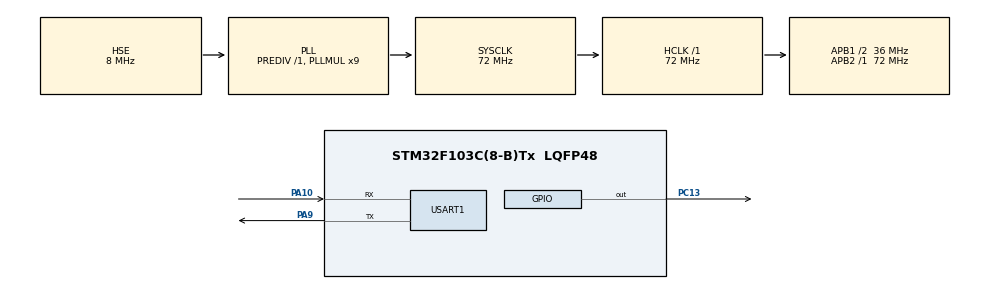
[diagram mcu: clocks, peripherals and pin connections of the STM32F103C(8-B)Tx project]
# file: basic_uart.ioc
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Dma.Request0=USART1_RX
Dma.USART1_RX.0.Direction=DMA_PERIPH_TO_MEMORY
Dma.USART1_RX.0.Instance=DMA1_Channel5
Dma.USART1_RX.0.MemDataAlignment=DMA_MDATAALIGN_BYTE
Dma.USART1_RX.0.MemInc=DMA_MINC_ENABLE
Dma.USART1_RX.0.Mode=DMA_CIRCULAR
Dma.USART1_RX.0.PeriphDataAlignment=DMA_PDATAALIGN_BYTE
Dma.USART1_RX.0.PeriphInc=DMA_PINC_DISABLE
Dma.USART1_RX.0.Priority=DMA_PRIORITY_LOW
Mcu.Family=STM32F1
Mcu.Name=STM32F103C(8-B)Tx
Mcu.Package=LQFP48
NVIC.DMA1_Channel5_IRQn=true\:0\:0\:false\:false\:true
NVIC.PriorityGroup=NVIC_PRIORITYGROUP_4
NVIC.USART1_IRQn=true\:0\:0\:false\:false\:true
PA10.Mode=Asynchronous
PA10.Signal=USART1_RX
PA13.Mode=Serial_Wire
PA13.Signal=SYS_JTMS-SWDIO
PA14.Mode=Serial_Wire
PA14.Signal=SYS_JTCK-SWCLK
PA9.Mode=Asynchronous
PA9.Signal=USART1_TX
PC13-TAMPER-RTC.Signal=GPIO_Output
PD0-OSC_IN.Mode=HSE-External-Oscillator
PD0-OSC_IN.Signal=RCC_OSC_IN
PD1-OSC_OUT.Mode=HSE-External-Oscillator
PD1-OSC_OUT.Signal=RCC_OSC_OUT
ProjectManager.HeapSize=0x200
ProjectManager.StackSize=0x400
ProjectManager.TargetToolchain=Makefile
RCC.AHBFreq_Value=72000000
RCC.APB1CLKDivider=RCC_HCLK_DIV2
RCC.APB1Freq_Value=36000000
RCC.APB1TimFreq_Value=72000000
RCC.APB2Freq_Value=72000000
RCC.APB2TimFreq_Value=72000000
RCC.HCLKFreq_Value=72000000
RCC.PLLMUL=RCC_PLL_MUL9
RCC.PLLSourceVirtual=RCC_PLLSOURCE_HSE
RCC.SYSCLKFreq_VALUE=72000000
RCC.SYSCLKSource=RCC_SYSCLKSOURCE_PLLCLK
RCC.USBFreq_Value=72000000
USART1.VirtualMode=VM_ASYNC
board=basic_uart

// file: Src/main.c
/**
  ******************************************************************************
  * File Name          : main.c
  * Description        : Main program body
  ******************************************************************************
  ** This notice applies to any and all portions of this file
  * that are not between comment pairs USER CODE BEGIN and
  * USER CODE END. Other portions of this file, whether
  * inserted by the user or by software development tools
  * are owned by their respective copyright owners.
  *
  * COPYRIGHT(c) 2017 STMicroelectronics
  *
  * Redistribution and use in source and binary forms, with or without modification,
  * are permitted provided that the following conditions are met:
  *   1. Redistributions of source code must retain the above copyright notice,
  *      this list of conditions and the following disclaimer.
  *   2. Redistributions in binary form must reproduce the above copyright notice,
  *      this list of conditions and the following disclaimer in the documentation
  *      and/or other materials provided with the distribution.
  *   3. Neither the name of STMicroelectronics nor the names of its contributors
  *      may be used to endorse or promote products derived from this software
  *      without specific prior written permission.
  *
  * THIS SOFTWARE IS PROVIDED BY THE COPYRIGHT HOLDERS AND CONTRIBUTORS "AS IS"
  * AND ANY EXPRESS OR IMPLIED WARRANTIES, INCLUDING, BUT NOT LIMITED TO, THE
  * IMPLIED WARRANTIES OF MERCHANTABILITY AND FITNESS FOR A PARTICULAR PURPOSE ARE
  * DISCLAIMED. IN NO EVENT SHALL THE COPYRIGHT HOLDER OR CONTRIBUTORS BE LIABLE
  * FOR ANY DIRECT, INDIRECT, INCIDENTAL, SPECIAL, EXEMPLARY, OR CONSEQUENTIAL
  * DAMAGES (INCLUDING, BUT NOT LIMITED TO, PROCUREMENT OF SUBSTITUTE GOODS OR
  * SERVICES; LOSS OF USE, DATA, OR PROFITS; OR BUSINESS INTERRUPTION) HOWEVER
  * CAUSED AND ON ANY THEORY OF LIABILITY, WHETHER IN CONTRACT, STRICT LIABILITY,
  * OR TORT (INCLUDING NEGLIGENCE OR OTHERWISE) ARISING IN ANY WAY OUT OF THE USE
  * OF THIS SOFTWARE, EVEN IF ADVISED OF THE POSSIBILITY OF SUCH DAMAGE.
  *
  ******************************************************************************
  */
#include "main.h"
#include "stm32f1xx_hal.h"
#include "dma.h"
#include "usart.h"
#include "gpio.h"

/* USER CODE BEGIN PV */
/* Private variables ---------------------------------------------------------*/
uint8_t received[] = "          \n\r";
uint8_t num_rx_rounds = 0;
const uint8_t use_dma = 1;

/* USER CODE END PV */

void SystemClock_Config(void);

/* USER CODE BEGIN PFP */
/* Private function prototypes -----------------------------------------------*/

/* USER CODE END PFP */

/* USER CODE BEGIN 0 */
void delayLoop() {
        volatile uint32_t delayCount = 100000; // volatile, um "Wegoptimieren" zu vermeinden
                                               //(http://en.wikipedia.org/wiki/Volatile_variable)
        while (delayCount > 0) {
                delayCount--;
        }
}

void btoa(uint8_t i, uint8_t *str)
{
  str[2] = '0' + i%10;
  str[1] = '0' + (i/10)%10;
  str[0] = '0' + (i/100)%10;
}

// to talk to UART minicom --baudrate 115200 --device /dev/ttyUSB0
void HAL_UART_TxCpltCallback(UART_HandleTypeDef *huart)
{
  HAL_UART_StateTypeDef state = HAL_UART_GetState(huart);
  if (state == HAL_UART_STATE_READY) {

  } else {

  }
}

void HAL_UART_RxCpltCallback (UART_HandleTypeDef *huart)
{
  num_rx_rounds++;

  if (use_dma) {
    // don't need to do anything. DMA is circular
  } else {
    __attribute__((unused)) HAL_StatusTypeDef state;

    // -3 because of \n \r and 0x0 to end the string
    state = HAL_UART_Receive_IT(&huart1, received, sizeof(received)-3);
  }
}

/* USER CODE END 0 */

int main(void)
{

  /* MCU Configuration----------------------------------------------------------*/

  /* Reset of all peripherals, Initializes the Flash interface and the Systick. */
  HAL_Init();

  /* Configure the system clock */
  SystemClock_Config();

  /* Initialize all configured peripherals */
  MX_GPIO_Init();
  MX_DMA_Init();
  MX_USART1_UART_Init();

  /* USER CODE BEGIN 2 */
  uint8_t themessage[]      = "E.T. is phoning home. Anyone there? received xxx\r\n";
  uint8_t theothermessage[] = "Hey. I hate to interrupt, but...received     xxx\r\n";

  if (use_dma) {
    HAL_UART_Receive_DMA(&huart1, received, sizeof(received)-3);
  } else {
    HAL_UART_Receive_IT(&huart1, received, sizeof(received)-3);
  }

  /* USER CODE END 2 */

  /* Infinite loop */
  /* USER CODE BEGIN WHILE */
  uint8_t poll = 1;
  uint8_t lighton = 0;
  while (1)
  {
  /* USER CODE END WHILE */

  /* USER CODE BEGIN 3 */
    if ((HAL_GetTick() % 1000) == 0) {
      HAL_UART_StateTypeDef state = HAL_UART_GetState(&huart1);
      if (state == HAL_UART_STATE_READY ||
          state == HAL_UART_STATE_BUSY_RX) {

        __attribute__((unused)) HAL_StatusTypeDef tstate;
        if (poll) {
          btoa(huart1.RxXferCount, themessage+45);
          tstate = HAL_UART_Transmit(&huart1, themessage, sizeof(themessage), HAL_MAX_DELAY);
          tstate = HAL_UART_Transmit(&huart1, received, sizeof(received), HAL_MAX_DELAY);
        } else {
          btoa(huart1.RxXferCount, theothermessage+45);
          tstate = HAL_UART_Transmit_IT(&huart1, theothermessage, sizeof(theothermessage));
        }
        poll = !poll;
        state = HAL_UART_GetState(&huart1);
      }

      lighton = !lighton;
      if (lighton) {
        GPIOC->ODR |= GPIO_PIN_13;
      } else {
        GPIOC->ODR &= ~(GPIO_PIN_13);
      }
    }
  }
  /* USER CODE END 3 */

}

/** System Clock Configuration
*/
void SystemClock_Config(void)
{

  RCC_OscInitTypeDef RCC_OscInitStruct;
  RCC_ClkInitTypeDef RCC_ClkInitStruct;

    /**Initializes the CPU, AHB and APB busses clocks
    */
  RCC_OscInitStruct.OscillatorType = RCC_OSCILLATORTYPE_HSE;
  RCC_OscInitStruct.HSEState = RCC_HSE_ON;
  RCC_OscInitStruct.HSEPredivValue = RCC_HSE_PREDIV_DIV1;
  RCC_OscInitStruct.HSIState = RCC_HSI_ON;
  RCC_OscInitStruct.PLL.PLLState = RCC_PLL_ON;
  RCC_OscInitStruct.PLL.PLLSource = RCC_PLLSOURCE_HSE;
  RCC_OscInitStruct.PLL.PLLMUL = RCC_PLL_MUL9;
  if (HAL_RCC_OscConfig(&RCC_OscInitStruct) != HAL_OK)
  {
    _Error_Handler(__FILE__, __LINE__);
  }

    /**Initializes the CPU, AHB and APB busses clocks
    */
  RCC_ClkInitStruct.ClockType = RCC_CLOCKTYPE_HCLK|RCC_CLOCKTYPE_SYSCLK
                              |RCC_CLOCKTYPE_PCLK1|RCC_CLOCKTYPE_PCLK2;
  RCC_ClkInitStruct.SYSCLKSource = RCC_SYSCLKSOURCE_PLLCLK;
  RCC_ClkInitStruct.AHBCLKDivider = RCC_SYSCLK_DIV1;
  RCC_ClkInitStruct.APB1CLKDivider = RCC_HCLK_DIV2;
  RCC_ClkInitStruct.APB2CLKDivider = RCC_HCLK_DIV1;

  if (HAL_RCC_ClockConfig(&RCC_ClkInitStruct, FLASH_LATENCY_2) != HAL_OK)
  {
    _Error_Handler(__FILE__, __LINE__);
  }

    /**Configure the Systick interrupt time
    */
  HAL_SYSTICK_Config(HAL_RCC_GetHCLKFreq()/1000);

    /**Configure the Systick
    */
  HAL_SYSTICK_CLKSourceConfig(SYSTICK_CLKSOURCE_HCLK);

  /* SysTick_IRQn interrupt configuration */
  HAL_NVIC_SetPriority(SysTick_IRQn, 0, 0);
}

void _Error_Handler(char * file, int line)
{
  while(1)
  {
  }
}

/************************ (C) COPYRIGHT STMicroelectronics *****END OF FILE****/
